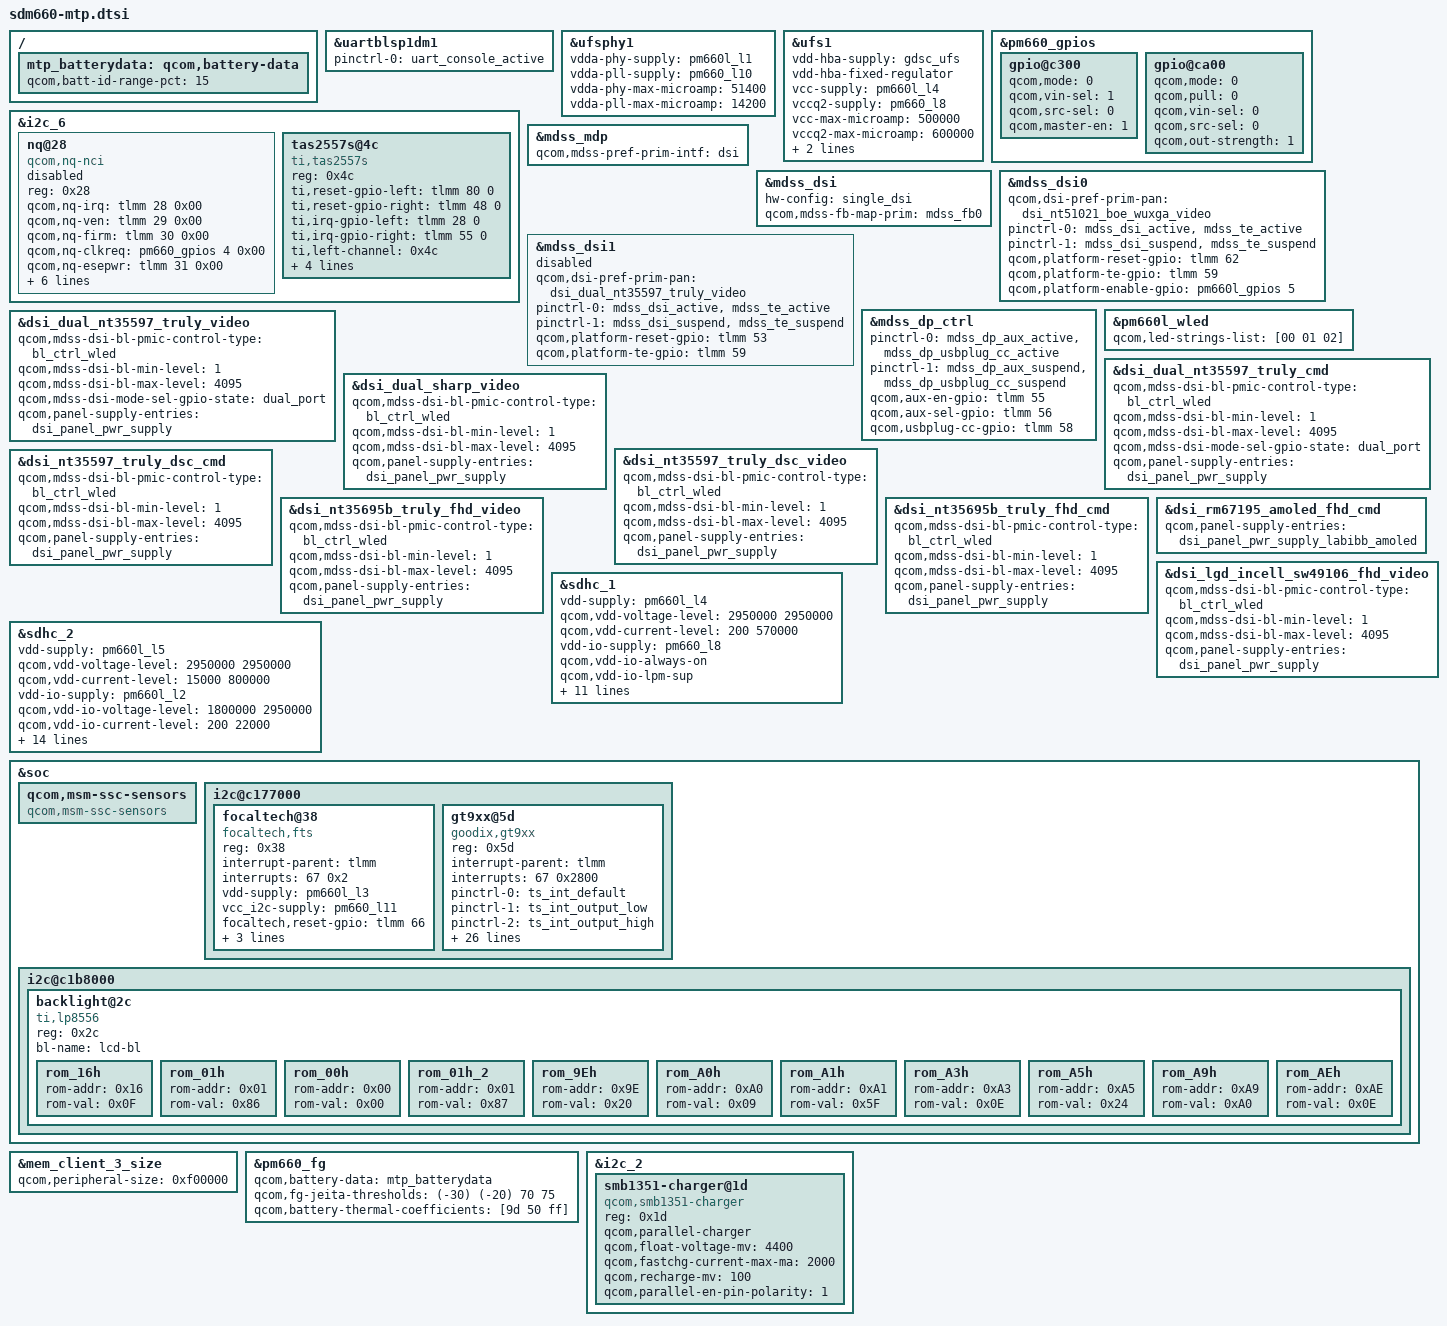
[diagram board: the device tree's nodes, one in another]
/* Copyright (c) 2016-2018, The Linux Foundation. All rights reserved.
 * Copyright (C) 2018 XiaoMi, Inc.
 *
 * This program is free software; you can redistribute it and/or modify
 * it under the terms of the GNU General Public License version 2 and
 * only version 2 as published by the Free Software Foundation.
 *
 * This program is distributed in the hope that it will be useful,
 * but WITHOUT ANY WARRANTY; without even the implied warranty of
 * MERCHANTABILITY or FITNESS FOR A PARTICULAR PURPOSE.  See the
 * GNU General Public License for more details.
 */

#include "sdm660-pinctrl.dtsi"
#include "sdm660-camera-sensor-mtp.dtsi"
/ {
	mtp_batterydata: qcom,battery-data {
		qcom,batt-id-range-pct = <15>;
		#include "batterydata-zql5018-6000mah.dtsi"
		#include "batterydata-zql6019-8600mah.dtsi"
	};
};

&uartblsp1dm1 {
	status = "ok";
	pinctrl-names = "default";
	pinctrl-0 = <&uart_console_active>;
};

&ufsphy1 {
	vdda-phy-supply = <&pm660l_l1>;
	vdda-pll-supply = <&pm660_l10>;
	vdda-phy-max-microamp = <51400>;
	vdda-pll-max-microamp = <14200>;
	status = "ok";
};

&ufs1 {
	vdd-hba-supply = <&gdsc_ufs>;
	vdd-hba-fixed-regulator;
	vcc-supply = <&pm660l_l4>;
	vccq2-supply = <&pm660_l8>;
	vcc-max-microamp = <500000>;
	vccq2-max-microamp = <600000>;
	qcom,vddp-ref-clk-supply = <&pm660_l1>;
	qcom,vddp-ref-clk-max-microamp = <100>;

	status = "ok";
};

&pm660_gpios {
	/* GPIO 4 (NFC_CLK_REQ) */
	gpio@c300 {
		qcom,mode = <0>;
		qcom,vin-sel = <1>;
		qcom,src-sel = <0>;
		qcom,master-en = <1>;
		status = "okay";
	};

	/* GPIO 11 for Home Key */
	gpio@ca00 {
		status = "okay";
		qcom,mode = <0>;
		qcom,pull = <0>;
		qcom,vin-sel = <0>;
		qcom,src-sel = <0>;
		qcom,out-strength = <1>;
	};
};

&i2c_6 { /* BLSP1 QUP6 (NFC) */
	status = "okay";
	nq@28 {
		status = "disabled";
		compatible = "qcom,nq-nci";
		reg = <0x28>;
		qcom,nq-irq = <&tlmm 28 0x00>;
		qcom,nq-ven = <&tlmm 29 0x00>;
		qcom,nq-firm = <&tlmm 30 0x00>;
		qcom,nq-clkreq = <&pm660_gpios 4 0x00>;
		qcom,nq-esepwr = <&tlmm 31 0x00>;
		interrupt-parent = <&tlmm>;
		qcom,clk-src = "BBCLK3";
		interrupts = <28 0>;
		interrupt-names = "nfc_irq";
		pinctrl-names = "nfc_active", "nfc_suspend";
		pinctrl-0 = <&nfc_int_active &nfc_enable_active>;
		pinctrl-1 = <&nfc_int_suspend &nfc_enable_suspend>;
		clocks = <&clock_rpmcc RPM_LN_BB_CLK3_PIN>;
		clock-names = "ref_clk";
	};
	tas2557s@4c {
		compatible = "ti,tas2557s";
		reg = <0x4c>;
		ti,reset-gpio-left = <&tlmm 80 0>;
		ti,reset-gpio-right = <&tlmm 48 0>;
		ti,irq-gpio-left = <&tlmm 28 0>;
		ti,irq-gpio-right = <&tlmm 55 0>;
		ti,left-channel = <0x4c>;
		ti,right-channel = <0x4e>;
		ti,echo-ref = <0>;   /* 0, left channel; 1, right channel; 2, both */
		ti,i2s-bits = <16>;   /* support 16, 24, 32 */
		ti,bypass-tmax = <0>;   /* 0, not bypass; 1, bypass */
		status = "ok";
	};
};

&mdss_mdp {
	qcom,mdss-pref-prim-intf = "dsi";
};

&mdss_dsi {
	hw-config = "single_dsi";
	qcom,mdss-fb-map-prim = <&mdss_fb0>;
};

&mdss_dsi0 {
	qcom,dsi-pref-prim-pan = <&dsi_nt51021_boe_wuxga_video>;
	pinctrl-names = "mdss_default", "mdss_sleep";
	pinctrl-0 = <&mdss_dsi_active &mdss_te_active>;
	pinctrl-1 = <&mdss_dsi_suspend &mdss_te_suspend>;
	qcom,platform-reset-gpio = <&tlmm 62 0>;
	qcom,platform-te-gpio = <&tlmm 59 0>;
	qcom,platform-enable-gpio = <&pm660l_gpios 5 0>; /* VDD3V3 LDO Enable */
};

&mdss_dsi1 {
	status = "disabled";
	qcom,dsi-pref-prim-pan = <&dsi_dual_nt35597_truly_video>;
	pinctrl-names = "mdss_default", "mdss_sleep";
	pinctrl-0 = <&mdss_dsi_active &mdss_te_active>;
	pinctrl-1 = <&mdss_dsi_suspend &mdss_te_suspend>;
	qcom,platform-reset-gpio = <&tlmm 53 0>;
	qcom,platform-te-gpio = <&tlmm 59 0>;
};

&mdss_dp_ctrl {
	pinctrl-names = "mdss_dp_active", "mdss_dp_sleep";
	pinctrl-0 = <&mdss_dp_aux_active &mdss_dp_usbplug_cc_active>;
	pinctrl-1 = <&mdss_dp_aux_suspend &mdss_dp_usbplug_cc_suspend>;
	qcom,aux-en-gpio = <&tlmm 55 0>;
	qcom,aux-sel-gpio = <&tlmm 56 0>;
	qcom,usbplug-cc-gpio = <&tlmm 58 0>;
};

&pm660l_wled {
	qcom,led-strings-list = [00 01 02];
};

&dsi_dual_nt35597_truly_video {
	qcom,mdss-dsi-bl-pmic-control-type = "bl_ctrl_wled";
	qcom,mdss-dsi-bl-min-level = <1>;
	qcom,mdss-dsi-bl-max-level = <4095>;
	qcom,mdss-dsi-mode-sel-gpio-state = "dual_port";
	qcom,panel-supply-entries = <&dsi_panel_pwr_supply>;
};

&dsi_dual_nt35597_truly_cmd {
	qcom,mdss-dsi-bl-pmic-control-type = "bl_ctrl_wled";
	qcom,mdss-dsi-bl-min-level = <1>;
	qcom,mdss-dsi-bl-max-level = <4095>;
	qcom,mdss-dsi-mode-sel-gpio-state = "dual_port";
	qcom,panel-supply-entries = <&dsi_panel_pwr_supply>;
};

&dsi_dual_sharp_video {
	qcom,mdss-dsi-bl-pmic-control-type = "bl_ctrl_wled";
	qcom,mdss-dsi-bl-min-level = <1>;
	qcom,mdss-dsi-bl-max-level = <4095>;
	qcom,panel-supply-entries = <&dsi_panel_pwr_supply>;
};

&dsi_nt35597_truly_dsc_video {
	qcom,mdss-dsi-bl-pmic-control-type = "bl_ctrl_wled";
	qcom,mdss-dsi-bl-min-level = <1>;
	qcom,mdss-dsi-bl-max-level = <4095>;
	qcom,panel-supply-entries = <&dsi_panel_pwr_supply>;
};

&dsi_nt35597_truly_dsc_cmd {
	qcom,mdss-dsi-bl-pmic-control-type = "bl_ctrl_wled";
	qcom,mdss-dsi-bl-min-level = <1>;
	qcom,mdss-dsi-bl-max-level = <4095>;
	qcom,panel-supply-entries = <&dsi_panel_pwr_supply>;
};

&dsi_nt35695b_truly_fhd_video {
	qcom,mdss-dsi-bl-pmic-control-type = "bl_ctrl_wled";
	qcom,mdss-dsi-bl-min-level = <1>;
	qcom,mdss-dsi-bl-max-level = <4095>;
	qcom,panel-supply-entries = <&dsi_panel_pwr_supply>;
};

&dsi_nt35695b_truly_fhd_cmd {
	qcom,mdss-dsi-bl-pmic-control-type = "bl_ctrl_wled";
	qcom,mdss-dsi-bl-min-level = <1>;
	qcom,mdss-dsi-bl-max-level = <4095>;
	qcom,panel-supply-entries = <&dsi_panel_pwr_supply>;
};

&dsi_rm67195_amoled_fhd_cmd {
	qcom,panel-supply-entries = <&dsi_panel_pwr_supply_labibb_amoled>;
};

&dsi_lgd_incell_sw49106_fhd_video {
	qcom,mdss-dsi-bl-pmic-control-type = "bl_ctrl_wled";
	qcom,mdss-dsi-bl-min-level = <1>;
	qcom,mdss-dsi-bl-max-level = <4095>;
	qcom,panel-supply-entries = <&dsi_panel_pwr_supply>;
};

&sdhc_1 {
	/* device core power supply */
	vdd-supply = <&pm660l_l4>;
	qcom,vdd-voltage-level = <2950000 2950000>;
	qcom,vdd-current-level = <200 570000>;

	/* device communication power supply */
	vdd-io-supply = <&pm660_l8>;
	qcom,vdd-io-always-on;
	qcom,vdd-io-lpm-sup;
	qcom,vdd-io-voltage-level = <1800000 1800000>;
	qcom,vdd-io-current-level = <200 325000>;

	pinctrl-names = "active", "sleep";
	pinctrl-0 = <&sdc1_clk_on &sdc1_cmd_on &sdc1_data_on &sdc1_rclk_on>;
	pinctrl-1 = <&sdc1_clk_off &sdc1_cmd_off &sdc1_data_off &sdc1_rclk_off>;

	qcom,clk-rates = <400000 20000000 25000000 50000000 100000000 192000000
								384000000>;

	qcom,nonremovable;
	qcom,bus-speed-mode = "HS400_1p8v", "HS200_1p8v", "DDR_1p8v";

	status = "ok";
};

&sdhc_2 {
	/* device core power supply */
	vdd-supply = <&pm660l_l5>;
	qcom,vdd-voltage-level = <2950000 2950000>;
	qcom,vdd-current-level = <15000 800000>;

	/* device communication power supply */
	vdd-io-supply = <&pm660l_l2>;
	qcom,vdd-io-voltage-level = <1800000 2950000>;
	qcom,vdd-io-current-level = <200 22000>;

	pinctrl-names = "active", "sleep";
	pinctrl-0 = <&sdc2_clk_on &sdc2_cmd_on &sdc2_data_on &sdc2_cd_on>;
	pinctrl-1 = <&sdc2_clk_off &sdc2_cmd_off &sdc2_data_off &sdc2_cd_off>;

	#address-cells = <0>;
	interrupt-parent = <&sdhc_2>;
	interrupts = <0 1 2>;
	#interrupt-cells = <1>;
	interrupt-map-mask = <0xffffffff>;
	interrupt-map = <0 &intc 0 0 125 0
			1 &intc 0 0 221 0
			2 &tlmm 54 0>;
	interrupt-names = "hc_irq", "pwr_irq", "status_irq";
	cd-gpios = <&tlmm 54 0x0>;

	qcom,clk-rates = <400000 20000000 25000000 50000000 100000000
								200000000>;
	qcom,bus-speed-mode = "SDR12", "SDR25", "SDR50", "DDR50", "SDR104";

	status = "ok";
};

&soc {
	qcom,msm-ssc-sensors {
		compatible = "qcom,msm-ssc-sensors";
	};
};

&mem_client_3_size {
	qcom,peripheral-size = <0xf00000>;
};

&pm660_fg {
	qcom,battery-data = <&mtp_batterydata>;
	qcom,fg-jeita-thresholds = <(-30) (-20) 70 75>;
	qcom,battery-thermal-coefficients = [9d 50 ff];
};

&i2c_2 {
	status = "ok";
	smb1351-charger@1d {
		compatible = "qcom,smb1351-charger";
		reg = <0x1d>;
		qcom,parallel-charger;
		qcom,float-voltage-mv = <4400>;
		qcom,fastchg-current-max-ma = <2000>;
		qcom,recharge-mv = <100>;
		qcom,parallel-en-pin-polarity = <1>;
	};
};

&soc {
		i2c@c177000 {
		status = "ok";
		focaltech@38{
			compatible = "focaltech,fts";
			reg = <0x38>;
			interrupt-parent = <&tlmm>;
			interrupts = <67 0x2>;
			vdd-supply = <&pm660l_l3>;
			vcc_i2c-supply = <&pm660_l11>;
			focaltech,reset-gpio = <&tlmm 66 0x00>;
			focaltech,irq-gpio = <&tlmm 67 0x02>;
			focaltech,max-touch-number = <10>;
			focaltech,display-coords =  <0 0 1200 1920>;

			};
				gt9xx@5d{
			compatible = "goodix,gt9xx";
			reg = <0x5d>;
			interrupt-parent = <&tlmm>;
			interrupts = <67 0x2800>;
			pinctrl-names = "default", "int-output-low","int-output-high", "int-input";
			pinctrl-0 = <&ts_int_default>;
			pinctrl-1 = <&ts_int_output_low>;
			pinctrl-2 = <&ts_int_output_high>;
			pinctrl-3 = <&ts_int_input>;

			reset-gpios = <&tlmm 66 0x0>;
			irq-gpios = <&tlmm 67 0x2800>;
			irq-flags = <2>;

			vdd_ana-supply = <&pm660l_l3>;
			vcc_i2c-supply = <&pm660_l11>;

			touchscreen-max-id = <10>;
			touchscreen-size-x = <1200>;
			touchscreen-size-y = <1920>;
			touchscreen-max-w = <512>;
			touchscreen-max-p = <512>;
			touchscreen-key-map = <172>, <158>; /*KEY_HOMEPAGE=172, KEY_BACK=158，KEY_MENU=139*/

			goodix,slide-wakeup = <1>;
			goodix,type-a-report = <0>;
			goodix,driver-send-cfg = <1>;
			goodix,resume-in-workqueue = <0>;
			goodix,int-sync = <1>;
			goodix,swap-x2y = <0>;
			goodix,esd-protect = <1>;
			goodix,auto-update = <1>;
			goodix,auto-update-cfg = <1>;
			goodix,power-off-sleep = <0>;
			goodix,pen-suppress-finger = <0>;
			goodix,charger-cmd = <0>;
			goodix,cfg-group0 = [
                                54 B0 04 80 07 6A 35 10 11 CC
				32 0F 5A 32 2E 45 00 02 00 02
				11 12 09 14 19 1F 14 95 B5 DE
				1C 1E B0 15 33 22 00 22 44 1C
				FA FA F0 00 00 00 00 32 5A 00
				02 10 2F 8A D0 78 55 19 64 04
				A8 12 00 97 18 00 8F 1C 00 8A
				23 00 89 2D 00 89 1E 23 24 2F
				00 00 00 00 00 00 11 00 00 0C
				1E 0A 4A 04 F7 14 0A 0F 23 0F
				3C 32 0F 00 00 00 01 42 00 00
				01 14 00 01 02 03 04 05 06 07
				08 09 0A 0B 0C 0D 0E 0F 10 11
				12 13 14 15 16 17 18 19 1A FF
				FF FF 2A 29 28 27 26 25 24 23
				22 21 20 1F 1E 1D 1C 1B 19 18
				17 16 15 14 13 12 11 10 0F 0E
				0D 0C 0B 0A 09 08 07 06 05 04
				03 02 01 00 A3 01
				];
		};
		};

		i2c@c1b8000 {
		status = "ok";
		backlight@2c {
			compatible = "ti,lp8556";
			reg = <0x2c>;

			bl-name = "lcd-bl";

			rom_16h {
				rom-addr = /bits/ 8 <0x16>;
				rom-val = /bits/ 8 <0x0F>; /* 4 output LED string enabled */
				};
			rom_01h {
				rom-addr = /bits/ 8 <0x01>;
				rom-val = /bits/ 8 <0x86>;
				};
			rom_00h {
				rom-addr = /bits/ 8 <0x00>;
				rom-val = /bits/ 8 <0x00>;
				};
			rom_01h_2 {
				rom-addr = /bits/ 8 <0x01>;
				rom-val = /bits/ 8 <0x87>; /* pwm + i2c combined mode after shaper block, 12-bit */
				};
			rom_9Eh {
				rom-addr = /bits/ 8 <0x9E>;
				rom-val = /bits/ 8 <0x20>;
				};
			rom_A0h {
				rom-addr = /bits/ 8 <0xA0>;
				rom-val = /bits/ 8 <0x09>; /* max current 23.5mA */
				};
			rom_A1h {
				rom-addr = /bits/ 8 <0xA1>;
				rom-val = /bits/ 8 <0x5F>; /* max current 23.5mA */
				};
			/* remove A2=21 , fix MIC recording 10KHz noise
			rom_A2h {
				rom-addr = /bits/ 8 <0xA2>;
				rom-val = /bits/ 8 <0x21>;
				};
			*/
			rom_A3h {
				rom-addr = /bits/ 8 <0xA3>;
				rom-val = /bits/ 8 <0x0E>; /* Select brightness change transition duration 000 = 0 ms (immediate change)*/
				};
			rom_A5h {
				rom-addr = /bits/ 8 <0xA5>;
				rom-val = /bits/ 8 <0x24>;
				};
			rom_A9h {
				rom-addr = /bits/ 8 <0xA9>;
				rom-val = /bits/ 8 <0xA0>;
				};
			rom_AEh {
				rom-addr = /bits/ 8 <0xAE>;
				rom-val = /bits/ 8 <0x0E>;
				};
			};
		};

};
